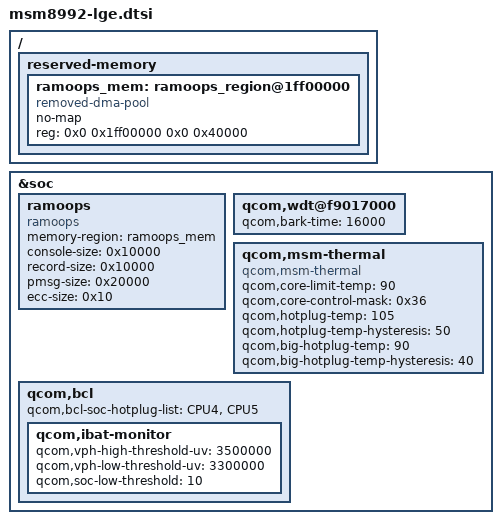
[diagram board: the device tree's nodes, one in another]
/* Copyright (c) 2015, LGE Inc. All rights reserved.
 * Copyright (c) 2014, The Linux Foundation. All rights reserved.
 *
 * This program is free software; you can redistribute it and/or modify
 * it under the terms of the GNU General Public License version 2 and
 * only version 2 as published by the Free Software Foundation.
 *
 * This program is distributed in the hope that it will be useful,
 * but WITHOUT ANY WARRANTY; without even the implied warranty of
 * MERCHANTABILITY or FITNESS FOR A PARTICULAR PURPOSE.  See the
 * GNU General Public License for more details.
 */

/ {
	reserved-memory {
		#address-cells = <2>;
		#size-cells = <2>;

		ramoops_mem: ramoops_region@1ff00000 {
			compatible = "removed-dma-pool";
			no-map;
			reg = <0x0 0x1ff00000 0x0 0x40000>;
		};
	};
};

&soc {
	ramoops {
		compatible = "ramoops";
		memory-region = <&ramoops_mem>;
		status = "okay";

		console-size = <0x10000>;
		record-size = <0x10000>;
		pmsg-size = <0x20000>;
		ecc-size = <0x10>;
	};

	qcom,wdt@f9017000 {
		qcom,bark-time = <16000>;
	};

	qcom,msm-thermal {
		compatible = "qcom,msm-thermal";
		qcom,core-limit-temp = <90>;
		qcom,core-control-mask = <0x36>;
		qcom,hotplug-temp = <105>;
		qcom,hotplug-temp-hysteresis = <50>;
		qcom,big-hotplug-temp = <90>;
		qcom,big-hotplug-temp-hysteresis = <40>;
	};

	qcom,bcl {
		qcom,bcl-soc-hotplug-list = <&CPU4 &CPU5>;
		qcom,ibat-monitor {
			qcom,vph-high-threshold-uv = <3500000>;
			qcom,vph-low-threshold-uv = <3300000>;
			qcom,soc-low-threshold = <10>;
		};
	};
};
